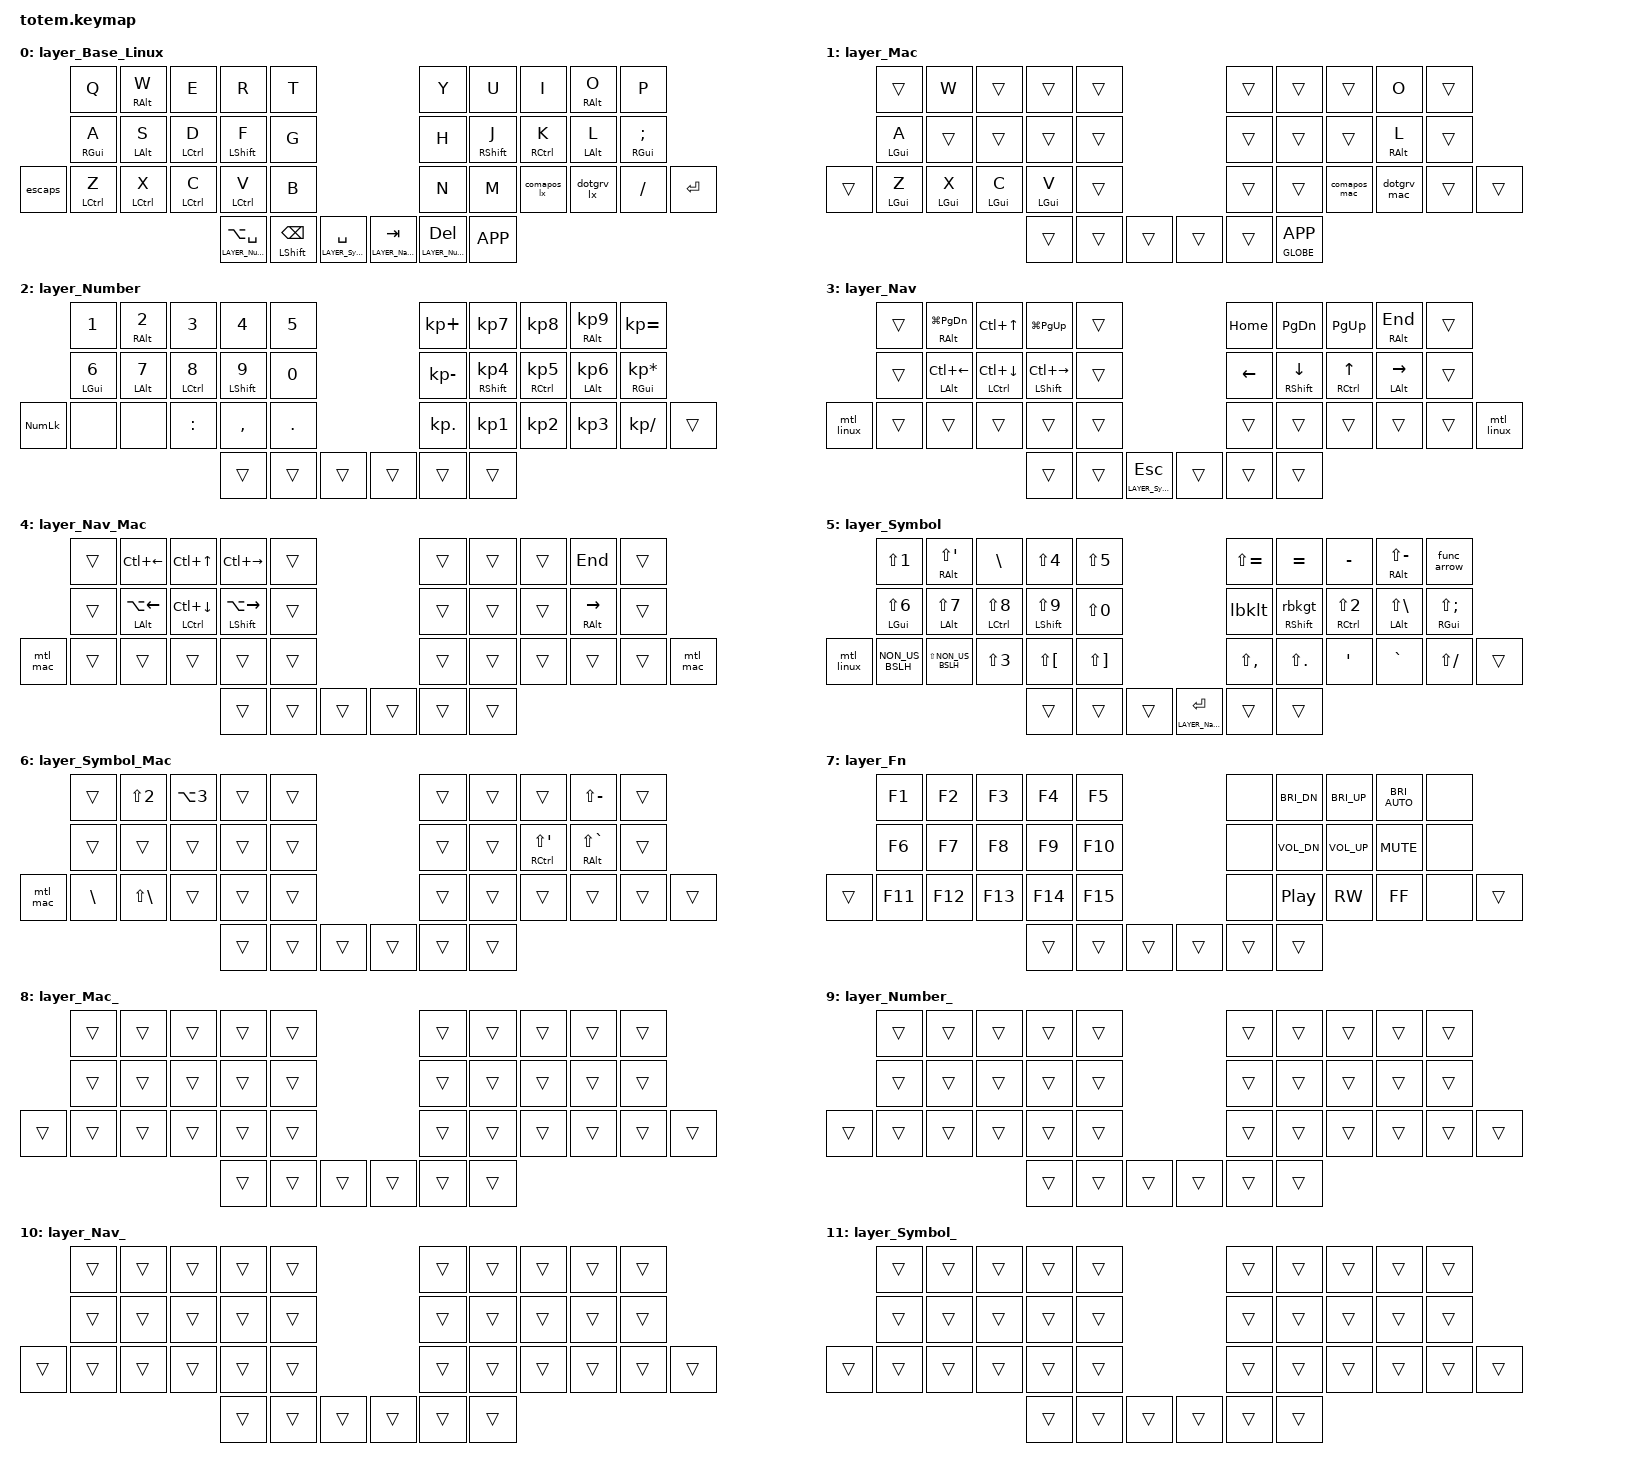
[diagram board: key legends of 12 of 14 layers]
//
//                                                        ▀▀▀▀▀     ▀▀▀▀▀          ▀▀█▀▀
//                                                        ▄▀▀▀▄  ▄  ▄▀▀▀▄  ▄  ▄▀▀▀▄  █  ▄▀▀▀▄
//                                                        █   █  █  █   █  █  █   █  █  █   █
//                                                         ▀▀▀   █   ▀▀▀   █   ▀▀▀   ▀   ▀▀▀
//                                                               █      ▄▄▄█▄▄▄    █   █
//                                                               ▀      █  █  █     █▄█
//                                                             ▀▀▀▀▀    █  █  █      ▀
//                                                                      ▀  ▀  ▀
//
// ▄▄▄▄▄▄▄▄▄▄▄▄▄▄▄▄▄▄▄▄▄▄▄▄▄▄▄▄▄▄▄▄▄▄▄▄▄▄▄▄▄▄▄▄▄▄▄▄▄▄▄▄▄▄▄▄▄▄▄▄▄▄▄▄▄▄▄▄▄▄▄▄▄▄▄▄▄▄▄▄▄▄▄▄▄▄▄▄▄▄▄▄▄▄▄▄▄▄▄▄▄▄▄▄▄▄▄▄▄▄▄▄▄▄▄▄▄▄▄▄▄▄▄▄▄▄▄▄▄▄▄▄▄▄▄▄▄▄▄▄▄▄▄▄▄▄▄▄▄


#include <behaviors.dtsi>
#include <dt-bindings/zmk/keys.h>
#include <dt-bindings/zmk/bt.h>
#include <dt-bindings/zmk/outputs.h>
#include <dt-bindings/zmk/rgb.h>
#include <dt-bindings/zmk/pointing.h>

#define LAYER_Base_Linux 0
#define LAYER_Mac 1
#define LAYER_Number 2
#define LAYER_Nav 3
#define LAYER_Nav_Mac 4
#define LAYER_Symbol 5
#define LAYER_Symbol_Mac 6
#define LAYER_Fn 7
#define LAYER_Mac_ 8
#define LAYER_Number_ 9
#define LAYER_Nav_ 10
#define LAYER_Symbol_ 11
#define LAYER_Fn_ 12
#define LAYER_Magic 13

// KEY_REPEATING_TERM defines how much time you have left (milliseconds)
// after tapping a key to hold it again in order to make it auto-repeat.
#define KEY_REPEATING_TERM 300 // "tap then hold" for key auto-repeat

// TAPPING_TERM defines how long you need to hold (milliseconds)
// mod keys in order to send their modifiers to the computer
// (i.e. "register" them) for mod-click mouse usage (e.g. Ctrl-Click).
#define TAPPING_TERM 200 // TAPPING_TERM + ALLOW_CROSSOVER_AFTER

&mt {
    flavor = "hold-preferred";
    tapping-term-ms = <TAPPING_TERM>;
    quick-tap-ms = <KEY_REPEATING_TERM>;
};

&lt {
    flavor = "hold-preferred";
    tapping-term-ms = <TAPPING_TERM>;
    quick-tap-ms = <KEY_REPEATING_TERM>;
};

/ {
#ifdef BT_DISC_CMD
    behaviors {
        bt_0: bt_0 {
            compatible = "zmk,behavior-tap-dance";
            label = "BT_0";
            #binding-cells = <0>;
            tapping-term-ms = <200>;
            bindings = <&bt_select_0>, <&bt BT_DISC 0>;
        };
        bt_1: bt_1 {
            compatible = "zmk,behavior-tap-dance";
            label = "BT_1";
            #binding-cells = <0>;
            tapping-term-ms = <200>;
            bindings = <&bt_select_1>, <&bt BT_DISC 1>;
        };
        bt_2: bt_2 {
            compatible = "zmk,behavior-tap-dance";
            label = "BT_2";
            #binding-cells = <0>;
            tapping-term-ms = <200>;
            bindings = <&bt_select_2>, <&bt BT_DISC 2>;
        };
        bt_3: bt_3 {
            compatible = "zmk,behavior-tap-dance";
            label = "BT_3";
            #binding-cells = <0>;
            tapping-term-ms = <200>;
            bindings = <&bt_select_3>, <&bt BT_DISC 3>;
        };
    };
    macros {
        bt_select_0: bt_select_0 {
            label = "BT_SELECT_0";
            compatible = "zmk,behavior-macro";
            #binding-cells = <0>;
            bindings
                = <&out OUT_BLE>,
                  <&bt BT_SEL 0>;
        };
        bt_select_1: bt_select_1 {
            label = "BT_SELECT_1";
            compatible = "zmk,behavior-macro";
            #binding-cells = <0>;
            bindings
                = <&out OUT_BLE>,
                  <&bt BT_SEL 1>;
        };
        bt_select_2: bt_select_2 {
            label = "BT_SELECT_2";
            compatible = "zmk,behavior-macro";
            #binding-cells = <0>;
            bindings
                = <&out OUT_BLE>,
                  <&bt BT_SEL 2>;
        };
        bt_select_3: bt_select_3 {
            label = "BT_SELECT_3";
            compatible = "zmk,behavior-macro";
            #binding-cells = <0>;
            bindings
                = <&out OUT_BLE>,
                  <&bt BT_SEL 3>;
        };
    };
#else
    macros {
        bt_0: bt_0 {
            label = "BT_0";
            compatible = "zmk,behavior-macro";
            #binding-cells = <0>;
            bindings
                = <&out OUT_BLE>,
                  <&bt BT_SEL 0>;
        };
        bt_1: bt_1 {
            label = "BT_1";
            compatible = "zmk,behavior-macro";
            #binding-cells = <0>;
            bindings
                = <&out OUT_BLE>,
                  <&bt BT_SEL 1>;
        };
        bt_2: bt_2 {
            label = "BT_2";
            compatible = "zmk,behavior-macro";
            #binding-cells = <0>;
            bindings
                = <&out OUT_BLE>,
                  <&bt BT_SEL 2>;
        };
        bt_3: bt_3 {
            label = "BT_3";
            compatible = "zmk,behavior-macro";
            #binding-cells = <0>;
            bindings
                = <&out OUT_BLE>,
                  <&bt BT_SEL 3>;
        };
    };
#endif
};

/* #define for key positions */
#define POS_LH_T1 34
#define POS_LH_T2 33
#define POS_LH_T3 32
#define POS_LH_C1R1 4
#define POS_LH_C1R2 14
#define POS_LH_C1R3 25
#define POS_LH_C2R1 3
#define POS_LH_C2R2 13
#define POS_LH_C2R3 24
#define POS_LH_C3R1 2
#define POS_LH_C3R2 12
#define POS_LH_C3R3 23
#define POS_LH_C4R1 1
#define POS_LH_C4R2 11
#define POS_LH_C4R3 22
#define POS_LH_C5R1 0
#define POS_LH_C5R2 10
#define POS_LH_C5R3 21
#define POS_LH_C6R3 20
#define POS_RH_T1 35
#define POS_RH_T2 36
#define POS_RH_T3 37
#define POS_RH_C1R1 26
#define POS_RH_C1R2 15
#define POS_RH_C1R3 27
#define POS_RH_C2R1 6
#define POS_RH_C2R2 16
#define POS_RH_C2R3 28
#define POS_RH_C3R1 7
#define POS_RH_C3R2 17
#define POS_RH_C3R3 29
#define POS_RH_C4R1 8
#define POS_RH_C4R2 18
#define POS_RH_C4R3 30
#define POS_RH_C5R1 9
#define POS_RH_C5R2 19
#define POS_RH_C5R3 31
#define POS_RH_C6R3 11

/* Custom Defined Behaviors */
/ {
  conditional_layers {
    compatible = "zmk,conditional-layers";
    mac {
      if-layers = <LAYER_Mac_>;
      then-layer = <LAYER_Mac>;
    };
    number {
      if-layers = <LAYER_Number_>;
      then-layer = <LAYER_Number>;
    };
    nav {
      if-layers = <LAYER_Nav_>;
      then-layer = <LAYER_Nav>;
    };
    nav_mac {
      if-layers = <LAYER_Nav_ LAYER_Mac_>;
      then-layer = <LAYER_Nav_Mac>;
    };
    symbol {
      if-layers = <LAYER_Symbol_>;
      then-layer = <LAYER_Symbol>;
    };
    symbol_mac {
      if-layers = <LAYER_Symbol_ LAYER_Mac_>;
      then-layer = <LAYER_Symbol_Mac>;
    };
    combined {
      if-layers = <LAYER_Symbol_ LAYER_Nav_>;
      then-layer = <LAYER_Fn>;
    };
    function {
      if-layers = <LAYER_Fn_>;
      then-layer = <LAYER_Fn>;
    };
  };
  
  behaviors {
    // Home row mod tap
    hrm: hrm {
        compatible = "zmk,behavior-hold-tap";
        #binding-cells = <2>;
        tapping-term-ms = <180>;
        bindings = <&kp>, <&kp>;
        flavor = "tap-preferred";
        quick-tap-ms = <300>;
    };

    // Hold for momentary layer, tap to toggle layer
    mtog: momentary_toggle {
      compatible = "zmk,behavior-hold-tap";
      #binding-cells = <2>;
      flavor = "hold-preferred";
      tapping-term-ms = <TAPPING_TERM>;
      quick-tap-ms = <KEY_REPEATING_TERM>;
      bindings = <&mo>, <&tog>;
    };

    // Hold for magic layer, tap to toggle mac layers, double tap to lock
    mtl_linux: magic_toggle_lock_linux {
      compatible = "zmk,behavior-tap-dance";
      #binding-cells = <0>;
      tapping-term-ms = <TAPPING_TERM>;
      bindings = <&mtog LAYER_Magic LAYER_Mac_ >, <&kp LG(L)>;
    };
    mtl_mac: magic_toggle_lock_mac {
      compatible = "zmk,behavior-tap-dance";
      #binding-cells = <0>;
      tapping-term-ms = <TAPPING_TERM>;
      bindings = <&mtog LAYER_Magic LAYER_Mac_ >, <&kp LG(LC(Q))>;
    };

    // Hold to toggle layer, tap for key press
    togtap: tap_toggle {
      compatible = "zmk,behavior-hold-tap";
      #binding-cells = <2>;
      flavor = "hold-preferred";
      tapping-term-ms = <TAPPING_TERM>;
      quick-tap-ms = <KEY_REPEATING_TERM>;
      bindings = <&tog>, <&kp>;
    };

    // Esc, Capslock when shifted
    escaps: esc_capslock {
      compatible = "zmk,behavior-mod-morph";
      #binding-cells = <0>;
      bindings = <&kp ESC>, <&kp CAPS>;
      mods = <(MOD_LSFT|MOD_RSFT)>;
    };

    // Comma, apostrophe when shifted - Linux
    comapos_lx: comma_apostrophe_linux {
      compatible = "zmk,behavior-mod-morph";
      #binding-cells = <0>;
      bindings = <&kp COMMA>, <&kp LS(N2)>;
      mods = <(MOD_LSFT|MOD_RSFT)>;
    };

    // Comma, apostrophe when shifted - MacOS
    comapos_mac: comma_apostrophe_mac {
      compatible = "zmk,behavior-mod-morph";
      #binding-cells = <0>;
      bindings = <&kp COMMA>, <&kp APOS>;
      mods = <(MOD_LSFT|MOD_RSFT)>;
    };

    // Dot, backtick when shifted - Linux
    dotgrv_lx: dot_grave_linux {
      compatible = "zmk,behavior-mod-morph";
      #binding-cells = <0>;
      bindings = <&kp DOT>, <&kp GRAVE>;
      mods = <(MOD_LSFT|MOD_RSFT)>;
    };

    // Dot, backtick when shifted - MacOS
    dotgrv_mac: dot_grave_mac {
      compatible = "zmk,behavior-mod-morph";
      #binding-cells = <0>;
      bindings = <&kp DOT>, <&kp GRAVE>;
      mods = <(MOD_LSFT|MOD_RSFT)>;
    };

    // Left square bracket, less-than when shifted
    lbklt: left_bracket_less_than {
      compatible = "zmk,behavior-mod-morph";
      #binding-cells = <0>;
      bindings = <&kp LBKT>, <&kp LT>;
      mods = <(MOD_LSFT|MOD_RSFT)>;
    };

    // Right square bracket, greater-than when shifted
    rbkgt: right_bracket_more_than {
      compatible = "zmk,behavior-mod-morph";
      #binding-cells = <0>;
      bindings = <&kp RBKT>, <&kp GT>;
      mods = <(MOD_LSFT|MOD_RSFT)>;
    };

    // Mod on hold, right square bracket on tap, greater-than when shifted - pass dummy parameter value for rbkgt
    mrbkgt: mod_right_bracket_more_than {
      compatible = "zmk,behavior-hold-tap";
      #binding-cells = <2>;
      flavor = "tap-preferred";
      tapping-term-ms = <TAPPING_TERM>;
      quick-tap-ms = <KEY_REPEATING_TERM>;
      bindings = <&kp>, <&rbkgt>;
    };

    // Hold for a key, Caps Lock on a tap - pass dummy parameter value for caps_lock
    hcl: hold_caps_lock {
        compatible = "zmk,behavior-hold-tap";
        #binding-cells = <2>;
        flavor = "hold-preferred";
        tapping_term_ms = <TAPPING_TERM>;
        bindings = <&kp>, <&caps_lock>;
    };
    
    // Hold for a key, Caps Word on a tap - pass dummy parameter value for caps_word
    hcw: hold_caps_word {
        compatible = "zmk,behavior-hold-tap";
        #binding-cells = <2>;
        flavor = "hold-preferred";
        tapping_term_ms = <TAPPING_TERM>;
        bindings = <&kp>, <&caps_word>;
    };
  };

  macros {
    // Caps lock with a brief paused hold, for MacOS
    caps_lock: caps_lock {
      compatible = "zmk,behavior-macro";
      #binding-cells = <0>;
      tap-ms = <100>;
      wait-ms = <0>;
      bindings
      = <&macro_tap &kp CAPSLOCK>
      ;
    };

    // Function arrow: =>
    func_arrow: function_arrow {
      compatible = "zmk,behavior-macro";
      label = "FUNCTION_ARROW";
      #binding-cells = <0>;
      tap-ms = <0>;
      wait-ms = <0>;
      bindings
      = <&macro_tap &kp EQUAL &kp GREATER_THAN>
      ;
    };

    // Arrow: ->
    arrow: arrow {
      compatible = "zmk,behavior-macro";
      label = "ARROW";
      #binding-cells = <0>;
      tap-ms = <0>;
      wait-ms = <0>;
      bindings
      = <&macro_tap &kp MINUS &kp GREATER_THAN>
      ;
    };

    // Activate bluetooth profile 0 and Linux layer
    bto_0: blue_tooth_profile_0_linux_layer {
      compatible = "zmk,behavior-macro";
      #binding-cells = <0>;
      bindings
        = <&macro_tap &bt_0>
        , <&macro_tap &to LAYER_Base_Linux>
        ;
    };

    // Activate bluetooth profile 1 and Mac layer
    bto_1: blue_tooth_profile_1_and_mac_layer {
      compatible = "zmk,behavior-macro";
      #binding-cells = <0>;
      bindings
        = <&macro_tap &bt_1>
        , <&macro_tap &to LAYER_Mac_>
        ;
    };

    // Activate bluetooth profile 2 and Mac layer
    bto_2: blue_tooth_profile_2_and_mac_layer {
      compatible = "zmk,behavior-macro";
      #binding-cells = <0>;
      bindings
        = <&macro_tap &bt_2>
        , <&macro_tap &to LAYER_Mac_>
        ;
    };
  };
};

/ {
    keymap {
        compatible = "zmk,keymap";


        layer_Base_Linux {
            bindings = <
           &kp Q         &hrm RALT W   &kp E         &kp R                        &kp T                                                                    &kp Y               &kp U         &kp I         &hrm RALT O  &kp P
           &hrm RGUI A   &hrm LALT S   &hrm LCTRL D  &hrm LSHFT F                 &kp G                                                                    &kp H               &hrm RSHFT J  &hrm RCTRL K  &hrm LALT L  &hrm RGUI SEMI
  &escaps  &hrm LCTRL Z  &hrm LCTRL X  &hrm LCTRL C  &hrm LCTRL V                 &kp B                                                                    &kp N               &kp M         &comapos_lx      &dotgrv_lx      &kp FSLH        &kp RET
                                                     &lt LAYER_Number_ LA(SPACE)  &mt LSHFT BSPC  &lt LAYER_Symbol_ SPACE        &lt LAYER_Nav_ TAB  &lt LAYER_Number_ DELETE  &kp K_APP
            >;
        };

        layer_Mac {
            bindings = <
          &trans       &kp W        &trans       &trans       &trans                          &trans  &trans  &trans        &kp O        &trans
          &hrm LGUI A  &trans       &trans       &trans       &trans                          &trans  &trans  &trans        &hrm RALT L  &trans
  &trans  &hrm LGUI Z  &hrm LGUI X  &hrm LGUI C  &hrm LGUI V  &trans                          &trans  &trans  &comapos_mac  &dotgrv_mac  &trans  &trans
                                                 &trans       &trans  &trans          &trans  &trans  &mt GLOBE K_APP
            >;
        };

        layer_Number {
            bindings = <
              &kp N1        &hrm RALT N2  &kp N3         &kp N4         &kp N5                         &kp KP_PLUS   &kp KP_N7         &kp KP_N8         &hrm RALT KP_N9  &kp KP_EQUAL
              &hrm LGUI N6  &hrm LALT N7  &hrm LCTRL N8  &hrm LSHFT N9  &kp N0                         &kp KP_MINUS  &hrm RSHFT KP_N4  &hrm RCTRL KP_N5  &hrm LALT KP_N6  &hrm RGUI KP_MULTIPLY
  &kp KP_NUM  &none         &none         &kp COLON      &kp COMMA      &kp DOT                        &kp KP_DOT    &kp KP_N1         &kp KP_N2         &kp KP_N3        &kp KP_SLASH           &trans
                                                         &trans         &trans   &trans        &trans  &trans        &trans
            >;
        };

        layer_Nav {
            bindings = <
              &trans  &hrm RALT LG(PG_DN)  &kp LC(UP)           &kp LG(PG_UP)         &trans                                       &kp HOME  &kp PG_DN        &kp PG_UP      &hrm RALT END    &trans
              &trans  &hrm LALT LC(LEFT)   &hrm LCTRL LC(DOWN)  &hrm LSHFT LC(RIGHT)  &trans                                       &kp LEFT  &hrm RSHFT DOWN  &hrm RCTRL UP  &hrm LALT RIGHT  &trans
  &mtl_linux  &trans  &trans               &trans               &trans                &trans                                       &trans    &trans           &trans         &trans           &trans  &mtl_linux
                                                                &trans                &trans  &lt LAYER_Symbol_ ESC        &trans  &trans    &trans
            >;
        };

        layer_Nav_Mac {
            bindings = <
            &trans  &kp LC(LEFT)        &kp LC(UP)           &kp LC(RIGHT)         &trans                        &trans  &trans  &trans  &kp END          &trans
            &trans  &hrm LALT LA(LEFT)  &hrm LCTRL LC(DOWN)  &hrm LSHFT LA(RIGHT)  &trans                        &trans  &trans  &trans  &hrm RALT RIGHT  &trans
  &mtl_mac  &trans  &trans              &trans               &trans                &trans                        &trans  &trans  &trans  &trans  &trans   &mtl_mac
                                                             &trans                &trans  &trans        &trans  &trans  &trans
            >;
        };

        layer_Symbol {
            bindings = <
              &kp LS(N1)        &hrm RALT LS(SQT)    &kp BSLH           &kp LS(N4)         &kp LS(N5)                                    &kp LS(EQUAL)         &kp EQUAL        &kp MINUS          &hrm RALT LS(MINUS)  &func_arrow
              &hrm LGUI LS(N6)  &hrm LALT LS(N7)     &hrm LCTRL LS(N8)  &hrm LSHFT LS(N9)  &kp LS(N0)                                    &lbklt                &mrbkgt RSHFT 0  &hrm RCTRL LS(N2)  &hrm LALT LS(BSLH)   &hrm RGUI LS(SEMI)
  &mtl_linux  &kp NON_US_BSLH   &kp LS(NON_US_BSLH)  &kp LS(N3)         &kp LS(LBKT)       &kp LS(RBKT)                                  &kp LS(COMMA)         &kp LS(DOT)      &kp SQT            &kp GRAVE            &kp LS(FSLH)        &trans
                                                                     &trans             &trans        &trans    &lt LAYER_Nav_ ENTER  &trans   &trans
            >;
        };

        layer_Symbol_Mac {
            bindings = <
            &trans    &kp LS(N2)    &kp LA(N3)  &trans  &trans                        &trans  &trans  &trans              &kp LS(MINUS)        &trans
            &trans    &trans        &trans      &trans  &trans                        &trans  &trans  &hrm RCTRL LS(SQT)  &hrm RALT LS(GRAVE)  &trans
  &mtl_mac  &kp BSLH  &kp LS(BSLH)  &trans      &trans  &trans                        &trans  &trans  &trans              &trans               &trans  &trans
                                                &trans  &trans  &trans        &trans  &trans  &trans
            >;
        };

        layer_Fn {
            bindings = <
          &kp F1   &kp F2   &kp F3   &kp F4   &kp F5                         &none   &kp C_BRI_DN  &kp C_BRI_UP  &kp C_BRI_AUTO  &none
          &kp F6   &kp F7   &kp F8   &kp F9   &kp F10                        &none   &kp C_VOL_DN  &kp C_VOL_UP  &kp C_MUTE      &none
  &trans  &kp F11  &kp F12  &kp F13  &kp F14  &kp F15                        &none   &kp C_PP      &kp C_RW      &kp C_FF        &none  &trans
                                     &trans   &trans   &trans        &trans  &trans  &trans
            >;
        };

        layer_Mac_ {
            bindings = <
          &trans  &trans  &trans  &trans  &trans                        &trans  &trans  &trans  &trans  &trans
          &trans  &trans  &trans  &trans  &trans                        &trans  &trans  &trans  &trans  &trans
  &trans  &trans  &trans  &trans  &trans  &trans                        &trans  &trans  &trans  &trans  &trans  &trans
                                  &trans  &trans  &trans        &trans  &trans  &trans
            >;
        };

        layer_Number_ {
            bindings = <
          &trans  &trans  &trans  &trans  &trans                        &trans  &trans  &trans  &trans  &trans
          &trans  &trans  &trans  &trans  &trans                        &trans  &trans  &trans  &trans  &trans
  &trans  &trans  &trans  &trans  &trans  &trans                        &trans  &trans  &trans  &trans  &trans  &trans
                                  &trans  &trans  &trans        &trans  &trans  &trans
            >;
        };

        layer_Nav_ {
            bindings = <
          &trans  &trans  &trans  &trans  &trans                        &trans  &trans  &trans  &trans  &trans
          &trans  &trans  &trans  &trans  &trans                        &trans  &trans  &trans  &trans  &trans
  &trans  &trans  &trans  &trans  &trans  &trans                        &trans  &trans  &trans  &trans  &trans  &trans
                                  &trans  &trans  &trans        &trans  &trans  &trans
            >;
        };

        layer_Symbol_ {
            bindings = <
          &trans  &trans  &trans  &trans  &trans                        &trans  &trans  &trans  &trans  &trans
          &trans  &trans  &trans  &trans  &trans                        &trans  &trans  &trans  &trans  &trans
  &trans  &trans  &trans  &trans  &trans  &trans                        &trans  &trans  &trans  &trans  &trans  &trans
                                  &trans  &trans  &trans        &trans  &trans  &trans
            >;
        };

        layer_Fn_ {
            bindings = <
          &trans  &trans  &trans  &trans  &trans                        &trans  &trans  &trans  &trans  &trans
          &trans  &trans  &trans  &trans  &trans                        &trans  &trans  &trans  &trans  &trans
  &trans  &trans  &trans  &trans  &trans  &trans                        &trans  &trans  &trans  &trans  &trans  &trans
                                  &trans  &trans  &trans        &trans  &trans  &trans
            >;
        };

        layer_Magic {
            bindings = <
          &bt BT_CLR   &trans  &trans  &trans  &trans                        &trans  &trans  &trans  &trans  &bt BT_CLR_ALL
          &bootloader  &trans  &trans  &trans  &trans                        &trans  &trans  &trans  &trans  &bootloader
  &trans  &sys_reset   &trans  &trans  &trans  &trans                        &trans  &trans  &trans  &trans  &sys_reset      &trans
                                       &bto_0  &bto_1  &bto_2        &trans  &trans  &trans
            >;
        };
    };
};

